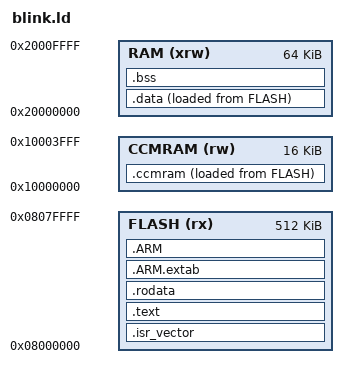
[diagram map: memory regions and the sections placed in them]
MEMORY
{
RAM (xrw)      : ORIGIN = 0x20000000, LENGTH = 64K
CCMRAM (rw)      : ORIGIN = 0x10000000, LENGTH = 16K
FLASH (rx)      : ORIGIN = 0x8000000, LENGTH = 512K
}

/* Define output sections */
SECTIONS
{
  /* The startup code goes first into FLASH */
  .isr_vector :
  {
    . = ALIGN(4);
    KEEP(*(.isr_vector)) /* Startup code */
    . = ALIGN(4);
  } >FLASH

  /* The program code and other data goes into FLASH */
  .text :
  {
    . = ALIGN(4);
    *(.text)           /* .text sections (code) */
    *(.text*)          /* .text* sections (code) */
    *(.glue_7)         /* glue arm to thumb code */
    *(.glue_7t)        /* glue thumb to arm code */
    *(.eh_frame)

    KEEP (*(.init))
    KEEP (*(.fini))

    . = ALIGN(4);
    _etext = .;        /* define a global symbols at end of code */
  } >FLASH

  /* Constant data goes into FLASH */
  .rodata :
  {
    . = ALIGN(4);
    *(.rodata)         /* .rodata sections (constants, strings, etc.) */
    *(.rodata*)        /* .rodata* sections (constants, strings, etc.) */
    . = ALIGN(4);
  } >FLASH

  .ARM.extab   : { *(.ARM.extab* .gnu.linkonce.armextab.*) } >FLASH
  .ARM : {
    __exidx_start = .;
    *(.ARM.exidx*)
    __exidx_end = .;
  } >FLASH

  
  /* Initialized data sections goes into RAM, load LMA copy after code */
  .data : 
  {
    . = ALIGN(4);
    _sdata = .;        /* create a global symbol at data start */
    *(.data)           /* .data sections */
    *(.data*)          /* .data* sections */

    . = ALIGN(4);
    _edata = .;        /* define a global symbol at data end */
  } >RAM AT> FLASH

  _siccmram = LOADADDR(.ccmram);

  /* CCM-RAM section 
  * 
  * IMPORTANT NOTE! 
  * If initialized variables will be placed in this section,
  * the startup code needs to be modified to copy the init-values.  
  */
  .ccmram :
  {
    . = ALIGN(4);
    _sccmram = .;       /* create a global symbol at ccmram start */
    *(.ccmram)
    *(.ccmram*)
    
    . = ALIGN(4);
    _eccmram = .;       /* create a global symbol at ccmram end */
  } >CCMRAM AT> FLASH

  
  /* Uninitialized data section */
  . = ALIGN(4);
  .bss :
  {
    /* This is used by the startup in order to initialize the .bss secion */
    _sbss = .;         /* define a global symbol at bss start */
    __bss_start__ = _sbss;
    *(.bss)
    *(.bss*)
    *(COMMON)

    . = ALIGN(4);
    _ebss = .;         /* define a global symbol at bss end */
    __bss_end__ = _ebss;
  } >RAM



  

  .ARM.attributes 0 : { *(.ARM.attributes) }
}
